# SF32LB52x register map
File version: 1.0
CPU: CM33 r0p1, little endian, MPU, FPU, 3 interrupt priority bits
Registers are 32-bit, read-write, reset 0x0 unless marked. A register's access mark holds for its fields unless they carry their own. Offsets are from the block's base; [hi:lo] are bit positions; {n}, {i} and the like mark numbered series.

## GPADC
Base 0x50087000
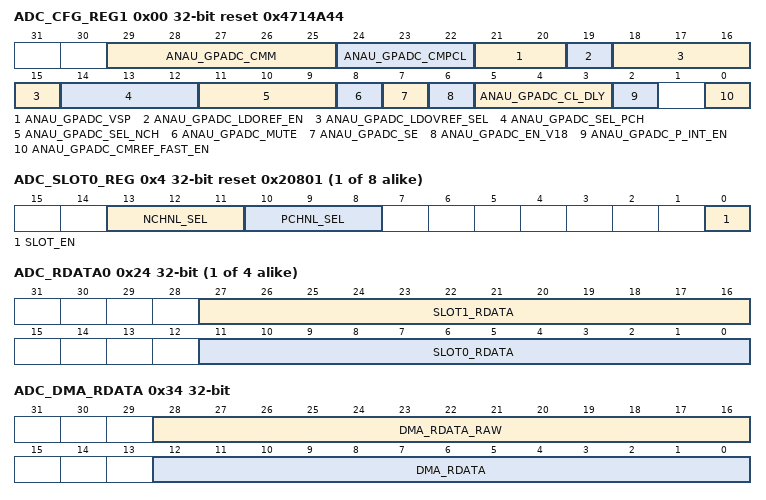
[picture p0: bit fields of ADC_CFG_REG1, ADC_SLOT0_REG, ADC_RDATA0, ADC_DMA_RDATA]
0x00 ADC_CFG_REG1 reset 0x4714A44 — ADC Analog Config Register 1
  [29:25] ANAU_GPADC_CMM — Tune CDAC CM voltage 375mV range (increasing) / 25mV step, 8: for 0.5V Vcm,in
  [24:22] ANAU_GPADC_CMPCL — Tune ADC comparator CL= 3: 40f, range: 10fF (0) ~ 80fF (7) / 10fF step
  [21:20] ANAU_GPADC_VSP — Set comparator input CM in sampling phase, 0.539V (0) / 0.578V (1) / 0.642V (2) / 0.784V (3)
  [19] ANAU_GPADC_LDOREF_EN — Enable LDORF for ADC VREF
  [18:15] ANAU_GPADC_LDOVREF_SEL — Set reference voltage for LDOREF, range = 0.35V(0) ~ 0.65V(15), step = 20mV
  [14:12] ANAU_GPADC_SEL_PCH — Select P-side input channel for GPADC, 0 for channel 0, 7 for channel 7, effective when force on
  [11:9] ANAU_GPADC_SEL_NCH — Select N-side input channel for GPADC, 0 for channel 0, 7 for channel 7, effective when force on
  [8] ANAU_GPADC_MUTE — Short GPADC P and N input to CMREF, i.e., VREF/2
  [7] ANAU_GPADC_SE — Set GPADC in single-ended mode, signal range at P-input: 0 ~ VREF
  [6] ANAU_GPADC_EN_V18
  [5:3] ANAU_GPADC_CL_DLY
  [2] ANAU_GPADC_P_INT_EN
  [0] ANAU_GPADC_CMREF_FAST_EN
{0x4+4i} ADC_SLOT{i}_REG reset 0x20801 (i=0..7) — ADC Slot{i} Config Register
  [13:11] NCHNL_SEL, [10:8] PCHNL_SEL, [0] SLOT_EN
{0x24+4i} ADC_RDATA{i} (i=0..3) — ADC Read Data{i}
  [27:16] SLOT{2i+1}_RDATA, [11:0] SLOT{2i}_RDATA
0x34 ADC_DMA_RDATA — ADC Read Data For DMA
  [28:16] DMA_RDATA_RAW, [12:0] DMA_RDATA
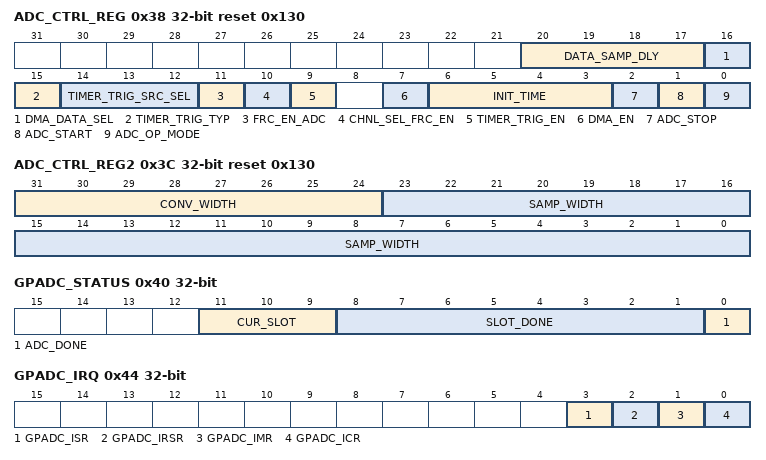
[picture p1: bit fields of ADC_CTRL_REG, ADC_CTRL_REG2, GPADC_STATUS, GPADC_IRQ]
0x38 ADC_CTRL_REG reset 0x130 — ADC Control Register
  [20:17] DATA_SAMP_DLY
  [16] DMA_DATA_SEL — 0: combined data 1: raw data
  [15] TIMER_TRIG_TYP — 0: pulse no edge detect needed 1: level,need edge detect
  [14:12] TIMER_TRIG_SRC_SEL — Timer trigger source select
  [11] FRC_EN_ADC — Enable GPADC core
  [10] CHNL_SEL_FRC_EN — Enable input channel setting in ADC_CFG_REG1
  [9] TIMER_TRIG_EN — Enable timer trigger function
  [7] DMA_EN — Enable DMA interface
  [6:3] INIT_TIME — GPADC will wait INIT_TIME ADCCLK cycles to start sample/conversion after being trigged
  [2] ADC_STOP — Write 1 to stop GPADC in continuous mode(need write 0 to clear)
  [1] ADC_START — Write 1 to start GPADC,(don't need clear )
  [0] ADC_OP_MODE — 0: single conversion mode 1: continuous conversion mode
0x3C ADC_CTRL_REG2 reset 0x130 — ADC Control Register2
  [31:24] CONV_WIDTH, [23:0] SAMP_WIDTH
0x40 GPADC_STATUS
  [11:9] CUR_SLOT, [8:1] SLOT_DONE, [0] ADC_DONE
0x44 GPADC_IRQ
  [3] GPADC_ISR, [2] GPADC_IRSR, [1] GPADC_IMR, [0] GPADC_ICR

## TSEN
Base 0x50089000
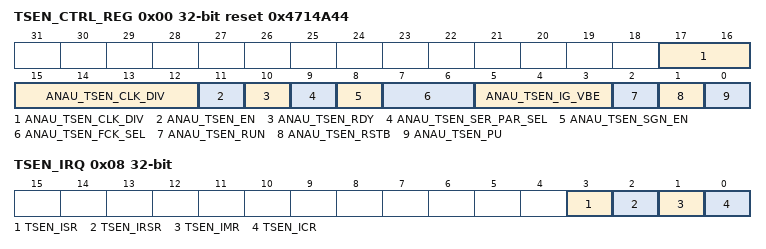
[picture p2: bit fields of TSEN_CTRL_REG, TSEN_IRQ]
0x00 TSEN_CTRL_REG reset 0x4714A44 — TSEN Analog Control Register
  [17:12] ANAU_TSEN_CLK_DIV — gen tsen clk by divide hclk by anau_tsen_clk_div
  [11] ANAU_TSEN_EN — Enable tsen digital module
  [10] ANAU_TSEN_RDY — tsen ready
  [9] ANAU_TSEN_SER_PAR_SEL — serial-parallel output selection
  [8] ANAU_TSEN_SGN_EN — signature-mode enable
  [7:6] ANAU_TSEN_FCK_SEL — select internal clock frequency
  [5:3] ANAU_TSEN_IG_VBE — bias current selection to tune vba
  [2] ANAU_TSEN_RUN — enable tsen run
  [1] ANAU_TSEN_RSTB — resetb for tsen
  [0] ANAU_TSEN_PU — power up tsen
0x04 TSEN_RDATA — Tsen Read Data
  [11:0] TSEN_RDATA
0x08 TSEN_IRQ
  [3] TSEN_ISR, [2] TSEN_IRSR, [1] TSEN_IMR, [0] TSEN_ICR

## WDT1 — Watchdog 1
Base 0x50094000
Same registers: WDT2 0x4000B000, IWDT 0x500CC000
0x00 WDT_CVR0 — WatchDog Counter Value 0
  [23:0] COUNT_VALUE_0 — Count Value for 1st TimeOut
0x04 WDT_CVR1 — WatchDog Counter Value 1
  [23:0] COUNT_VALUE_1 — Count Value for 2nd TimeOut
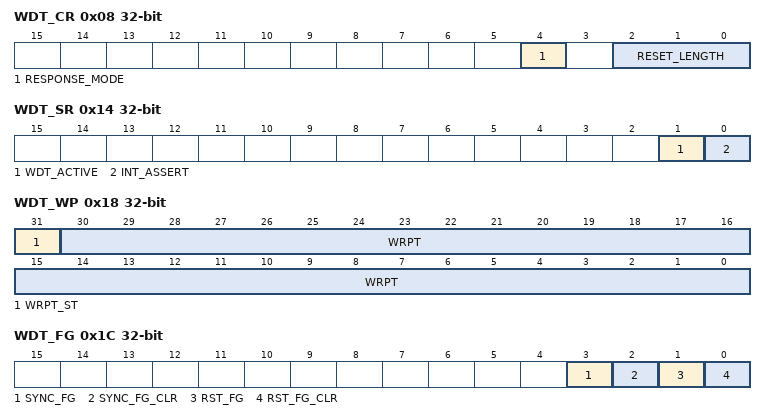
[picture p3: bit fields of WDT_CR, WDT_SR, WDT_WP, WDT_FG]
0x08 WDT_CR — WatchDog Control Register
  [4] RESPONSE_MODE — 0:reset only, 1:interrupt and reset
  [2:0] RESET_LENGTH — reset pulse length in number of wdt clock cycles
0x0C WDT_CCR — WatchDog Counter Control Register
  [7:0] COUNTER_CONTROL — SinglePulse /Write 8'h76 to restart, write8'h34 to stop, else do nothing
0x10 WDT_ICR — WatchDog Interrupt Clear Register
  [0] INT_CLR — SinglePulse /A pulse to clear interrupt
0x14 WDT_SR — WatchDog Status Register
  [1] WDT_ACTIVE — Watchdog runs when 1, else 0
  [0] INT_ASSERT — Interrupt assert when 1
0x18 WDT_WP — WatchDog Write Protect Register
  [31] WRPT_ST — 1 indicates write protect is active
  [30:0] WRPT — write 0x58ab99fc generate write_protect, write 0x51ff8621 to release
0x1C WDT_FG — WatchDog Flag Register
  [3] SYNC_FG — 1 indicates one transition from system clk to wdt clk has complicated
  [2] SYNC_FG_CLR — SinglePulse/A pulse to clear sync flag
  [1] RST_FG — 1 indicates wdt has already reset system
  [0] RST_FG_CLR — SinglePulse/A pulse to clear reset flag
